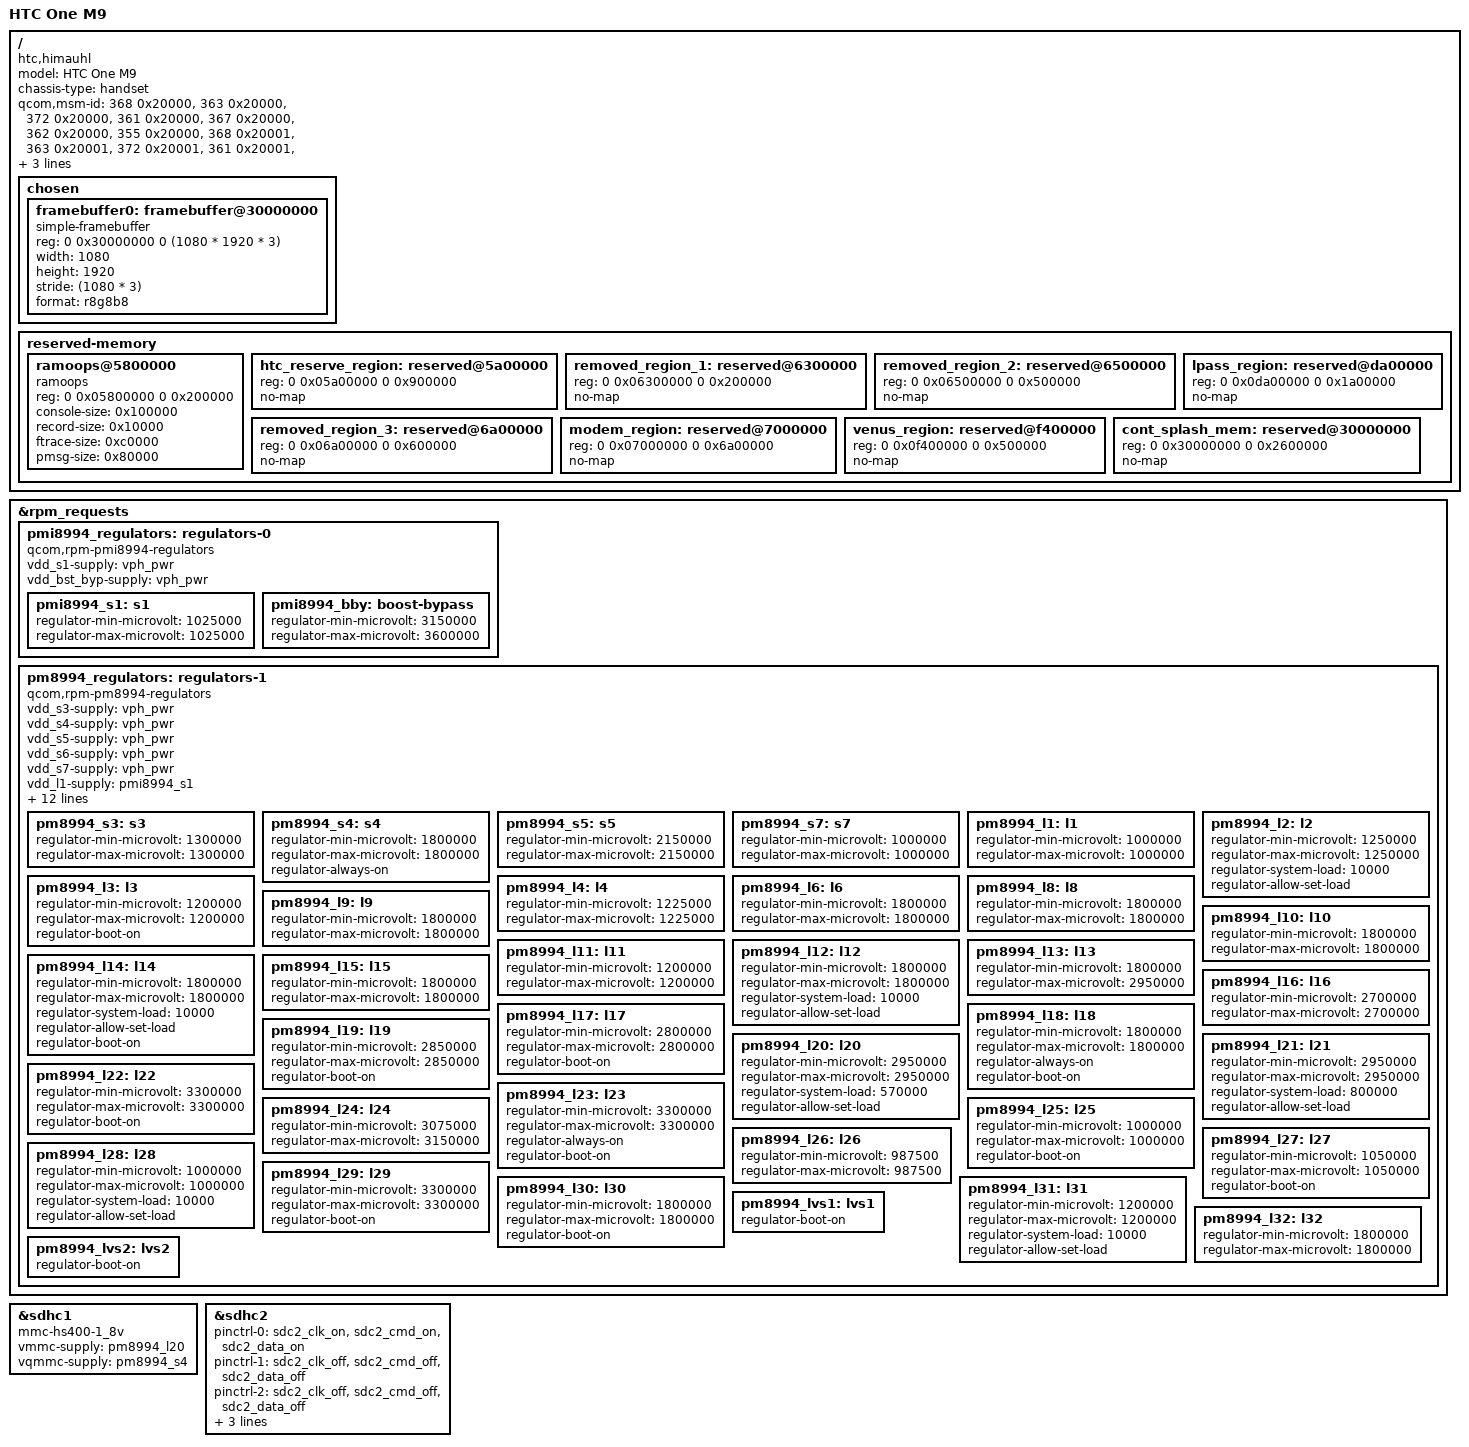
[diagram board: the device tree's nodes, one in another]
// SPDX-License-Identifier: GPL-2.0-only
/*
 * Copyright (c) 2014, The Linux Foundation. All rights reserved.
 * Copyright (c) 2023, Dominik Kobinski <dominikkobinski314<@gmail.com>
 */

/dts-v1/;

#include "msm8994.dtsi"
#include "pm8994.dtsi"
#include "pmi8994.dtsi"

/* cont_splash_mem has different memory mapping */
/delete-node/ &cont_splash_mem;

/ {
	model = "HTC One M9";
	compatible = "htc,himauhl", "qcom,msm8994";
	chassis-type = "handset";

	/* 
	 * required for bootloader to select correct board 
	 * the id's don't seem to correspond with actual 
	 * msm8994 msm-id, but for some reason the bootloader
	 * requires those
	*/
	qcom,msm-id = <368 0x20000>, <363 0x20000>, <372 0x20000>,
	              <361 0x20000>, <367 0x20000>, <362 0x20000>,
	              <355 0x20000>,
	              <368 0x20001>, <363 0x20001>, <372 0x20001>,
	              <361 0x20001>, <367 0x20001>, <362 0x20001>,
	              <355 0x20001>;
	qcom,board-id = <0x80 0>;
	qcom,pmic-id = <0x10009 0x1000A 0x0 0x0>;
	
	chosen {
		#address-cells = <2>;
		#size-cells = <2>;
		ranges;

		framebuffer0: framebuffer@30000000 {
			compatible = "simple-framebuffer";
			reg = <0 0x30000000 0 (1080 * 1920 * 3)>;
			width = <1080>;
			height = <1920>;
			stride = <(1080 * 3)>;
			format = "r8g8b8";
		};
	};

	reserved-memory {
		#address-cells = <2>;
		#size-cells = <2>;
		ranges;

		/* This is for getting crash logs using Android downstream kernels */
		ramoops@5800000 {
			compatible = "ramoops";
			reg = <0 0x05800000 0 0x200000>;
			console-size = <0x100000>;
			record-size = <0x10000>;
			ftrace-size = <0xc0000>;
			pmsg-size = <0x80000>;
		};

		htc_reserve_region: reserved@5a00000 {
			reg = <0 0x05a00000 0 0x900000>;
			no-map;
		};

		removed_region_1: reserved@6300000 {
			reg = <0 0x06300000 0 0x200000>;
			no-map;
		};

		removed_region_2: reserved@6500000 {
			reg = <0 0x06500000 0 0x500000>;
			no-map;
		};

		removed_region_3: reserved@6a00000 {
			reg = <0 0x06a00000 0 0x600000>;
			no-map;
		};

		modem_region: reserved@7000000 {
			reg = <0 0x07000000 0 0x6a00000>;
			no-map;
		};

		lpass_region: reserved@da00000 {
			reg = <0 0x0da00000 0 0x1a00000>;
			no-map;
		};

		venus_region: reserved@f400000 {
			reg = <0 0x0f400000 0 0x500000>;
			no-map;
		};

		cont_splash_mem: reserved@30000000 {
			reg = <0 0x30000000 0 0x2600000>;
			no-map;
		};
	};
};

&rpm_requests {
	pmi8994_regulators: regulators-0 {
		compatible = "qcom,rpm-pmi8994-regulators";

		vdd_s1-supply = <&vph_pwr>;
		vdd_bst_byp-supply = <&vph_pwr>;

		pmi8994_s1: s1 {
			regulator-min-microvolt = <1025000>;
			regulator-max-microvolt = <1025000>;
		};

		/* PMI8994 S2 + S3 - VDD_GFX supply */

		pmi8994_bby: boost-bypass {
			regulator-min-microvolt = <3150000>;
			regulator-max-microvolt = <3600000>;
		};
	};

	pm8994_regulators: regulators-1 {
		compatible = "qcom,rpm-pm8994-regulators";

		vdd_s3-supply = <&vph_pwr>;
		vdd_s4-supply = <&vph_pwr>;
		vdd_s5-supply = <&vph_pwr>;
		vdd_s6-supply = <&vph_pwr>;
		vdd_s7-supply = <&vph_pwr>;
		vdd_l1-supply = <&pmi8994_s1>;
		vdd_l2_l26_l28-supply = <&pm8994_s3>;
		vdd_l3_l11-supply = <&pm8994_s3>;
		vdd_l4_l27_l31-supply = <&pm8994_s3>;
		vdd_l6_l12_l32-supply = <&pm8994_s5>;
		vdd_l8_l16_l30-supply = <&vph_pwr>;
		vdd_l9_l10_l18_l22-supply = <&pmi8994_bby>;
		vdd_l13_l19_l23_l24-supply = <&pmi8994_bby>;
		vdd_l14_l15-supply = <&pm8994_s5>;
		vdd_l17_l29-supply = <&pmi8994_bby>;
		vdd_l20_l21-supply = <&pmi8994_bby>;
		vdd_l25-supply = <&pm8994_s3>;
		vdd_lvs1_2-supply = <&pm8994_s4>;

		/* S1, S2, S6 and S12 are managed by RPMPD */

		pm8994_s3: s3 {
			regulator-min-microvolt = <1300000>;
			regulator-max-microvolt = <1300000>;
		};

		pm8994_s4: s4 {
			regulator-min-microvolt = <1800000>;
			regulator-max-microvolt = <1800000>;
			regulator-always-on;
		};

		pm8994_s5: s5 {
			regulator-min-microvolt = <2150000>;
			regulator-max-microvolt = <2150000>;
		};

		pm8994_s7: s7 {
			regulator-min-microvolt = <1000000>;
			regulator-max-microvolt = <1000000>;
		};

		pm8994_l1: l1 {
			regulator-min-microvolt = <1000000>;
			regulator-max-microvolt = <1000000>;
		};

		pm8994_l2: l2 {
			regulator-min-microvolt = <1250000>;
			regulator-max-microvolt = <1250000>;
			regulator-system-load = <10000>;
			regulator-allow-set-load;
		};

		pm8994_l3: l3 {
			regulator-min-microvolt = <1200000>;
			regulator-max-microvolt = <1200000>;
			regulator-boot-on;
		};

		pm8994_l4: l4 {
			regulator-min-microvolt = <1225000>;
			regulator-max-microvolt = <1225000>;
		};

		/* L5 is inaccessible from RPM */

		pm8994_l6: l6 {
			regulator-min-microvolt = <1800000>;
			regulator-max-microvolt = <1800000>;
		};

		/* L7 is inaccessible from RPM */

		pm8994_l8: l8 {
			regulator-min-microvolt = <1800000>;
			regulator-max-microvolt = <1800000>;
		};

		pm8994_l9: l9 {
			regulator-min-microvolt = <1800000>;
			regulator-max-microvolt = <1800000>;
		};

		pm8994_l10: l10 {
			regulator-min-microvolt = <1800000>;
			regulator-max-microvolt = <1800000>;
		};

		pm8994_l11: l11 {
			regulator-min-microvolt = <1200000>;
			regulator-max-microvolt = <1200000>;
		};

		pm8994_l12: l12 {
			regulator-min-microvolt = <1800000>;
			regulator-max-microvolt = <1800000>;
			regulator-system-load = <10000>;
			regulator-allow-set-load;
		};

		pm8994_l13: l13 {
			regulator-min-microvolt = <1800000>;
			regulator-max-microvolt = <2950000>;
		};

		pm8994_l14: l14 {
			regulator-min-microvolt = <1800000>;
			regulator-max-microvolt = <1800000>;
			regulator-system-load = <10000>;
			regulator-allow-set-load;
			regulator-boot-on;
		};

		pm8994_l15: l15 {
			regulator-min-microvolt = <1800000>;
			regulator-max-microvolt = <1800000>;
		};

		pm8994_l16: l16 {
			regulator-min-microvolt = <2700000>;
			regulator-max-microvolt = <2700000>;
		};

		pm8994_l17: l17 {
			regulator-min-microvolt = <2800000>;
			regulator-max-microvolt = <2800000>;
			regulator-boot-on;
		};

		pm8994_l18: l18 {
			regulator-min-microvolt = <1800000>;
			regulator-max-microvolt = <1800000>;
			regulator-always-on;
			regulator-boot-on;
		};

		pm8994_l19: l19 {
			regulator-min-microvolt = <2850000>;
			regulator-max-microvolt = <2850000>;
			regulator-boot-on;
		};

		pm8994_l20: l20 {
			regulator-min-microvolt = <2950000>;
			regulator-max-microvolt = <2950000>;
			regulator-system-load = <570000>;
			regulator-allow-set-load;
		};

		pm8994_l21: l21 {
			regulator-min-microvolt = <2950000>;
			regulator-max-microvolt = <2950000>;
			regulator-system-load = <800000>;
			regulator-allow-set-load;
		};

		pm8994_l22: l22 {
			regulator-min-microvolt = <3300000>;
			regulator-max-microvolt = <3300000>;
			regulator-boot-on;
		};

		pm8994_l23: l23 {
			regulator-min-microvolt = <3300000>;
			regulator-max-microvolt = <3300000>;
			regulator-always-on;
			regulator-boot-on;
		};

		pm8994_l24: l24 {
			regulator-min-microvolt = <3075000>;
			regulator-max-microvolt = <3150000>;
		};

		pm8994_l25: l25 {
			regulator-min-microvolt = <1000000>;
			regulator-max-microvolt = <1000000>;
			regulator-boot-on;
		};

		pm8994_l26: l26 {
			regulator-min-microvolt = <987500>;
			regulator-max-microvolt = <987500>;
		};

		pm8994_l27: l27 {
			regulator-min-microvolt = <1050000>;
			regulator-max-microvolt = <1050000>;
			regulator-boot-on;
		};

		pm8994_l28: l28 {
			regulator-min-microvolt = <1000000>;
			regulator-max-microvolt = <1000000>;
			regulator-system-load = <10000>;
			regulator-allow-set-load;
		};

		pm8994_l29: l29 {
			regulator-min-microvolt = <3300000>;
			regulator-max-microvolt = <3300000>;
			regulator-boot-on;
		};

		pm8994_l30: l30 {
			regulator-min-microvolt = <1800000>;
			regulator-max-microvolt = <1800000>;
			regulator-boot-on;
		};

		pm8994_l31: l31 {
			regulator-min-microvolt = <1200000>;
			regulator-max-microvolt = <1200000>;
			regulator-system-load = <10000>;
			regulator-allow-set-load;
		};

		pm8994_l32: l32 {
			regulator-min-microvolt = <1800000>;
			regulator-max-microvolt = <1800000>;
		};

		pm8994_lvs1: lvs1 {
			regulator-boot-on;
		};
		pm8994_lvs2: lvs2 {
			regulator-boot-on;
		};
	};
};

&sdhc1 {
	status = "okay";
	mmc-hs400-1_8v;

	vmmc-supply = <&pm8994_l20>;
	vqmmc-supply = <&pm8994_s4>;
};

&sdhc2 {
	status = "okay";

	pinctrl-names = "default", "sleep";
	pinctrl-0 = <&sdc2_clk_on &sdc2_cmd_on &sdc2_data_on>;
	pinctrl-1 = <&sdc2_clk_off &sdc2_cmd_off &sdc2_data_off>;
	pinctrl-2 = <&sdc2_clk_off &sdc2_cmd_off &sdc2_data_off>;

	cd-gpios = <&pm8994_gpios 5 GPIO_ACTIVE_LOW>;

	vmmc-supply = <&pm8994_l21>;
	vqmmc-supply = <&pm8994_l13>;
};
